VERSION ""

NS_ :

BS_:

BU_: Test ECU

BO_ 513 Diag_Resp: 8 ECU
 SG_ Resp : 0|8@1- (1,0) [0|0] ""  Test

BO_ 512 Diag_Req: 8 Test
 SG_ Req : 0|8@1- (1,0) [0|0] "" Vector__XXX

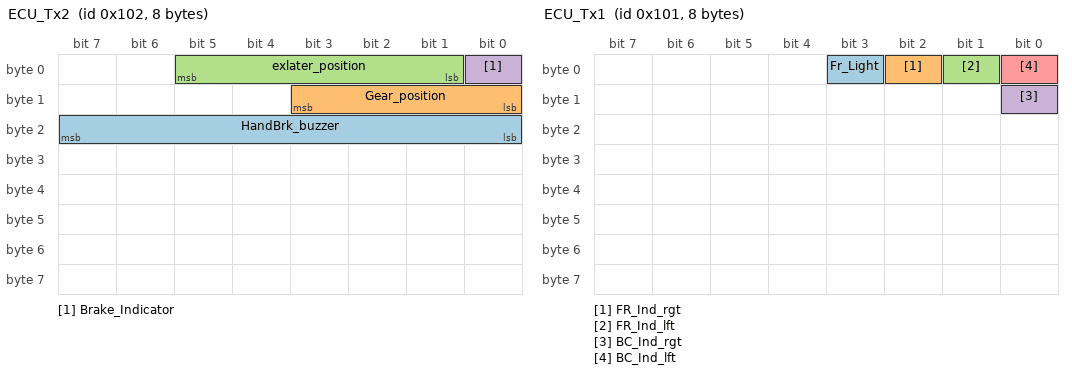
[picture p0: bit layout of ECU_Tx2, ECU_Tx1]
BO_ 258 ECU_Tx2: 8 ECU
 SG_ HandBrk_buzzer : 16|8@1- (1,0) [0|3] "" Vector__XXX
 SG_ Gear_position : 8|4@1+ (1,0) [0|6] ""  ECU
 SG_ exlater_position : 1|5@1+ (1,0) [0|31] ""  ECU
 SG_ Brake_Indicator : 0|1@1- (1,0) [0|1] ""  ECU

BO_ 257 ECU_Tx1: 8 ECU
 SG_ Fr_Light : 3|1@1- (1,0) [0|1] ""  ECU
 SG_ FR_Ind_rgt : 2|1@1- (1,0) [0|1] ""  ECU
 SG_ FR_Ind_lft : 1|1@1- (1,0) [0|1] ""  ECU
 SG_ BC_Ind_rgt : 8|1@1- (1,0) [0|1] ""  ECU
 SG_ BC_Ind_lft : 0|1@1- (1,0) [0|1] ""  ECU

BO_ 1281 ENGmsg: 8 ECU
 SG_ HandBreak_pos : 16|8@1- (1,0) [0|3] "" Vector__XXX
 SG_ Speed : 0|16@1+ (1,0) [0|65535] "" Vector__XXX

EV_ EnvKlemme30: 0 [0|1] "" 1 1 DUMMY_NODE_VECTOR0 Vector__XXX;

EV_ EnvKlemme15: 0 [0|1] "" 0 2 DUMMY_NODE_VECTOR0 Vector__XXX;

BA_DEF_ BU_  "NodeLayerModules" STRING ;
BA_DEF_ BO_  "GenMsgILSupport" ENUM  "No","Yes";
BA_DEF_  "NmBaseAddress" HEX 1024 1087;
BA_DEF_  "BusType" STRING ;
BA_DEF_ BO_  "GenMsgCycleTime" INT 0 50000;
BA_DEF_ BO_  "GenMsgSendType" ENUM  "Cyclic","NotUsed","NotUsed","NotUsed","NotUsed","NotUsed","NotUsed","IfActive","NoMsgSendType","NotUsed","vector_leerstring";
BA_DEF_ SG_  "GenSigSendType" ENUM  "Cyclic","OnWrite","OnWriteWithRepetition","OnChange","OnChangeWithRepetition","IfActive","IfActiveWithRepetition","NoSigSendType","NotUsed","NotUsed","NotUsed","NotUsed","NotUsed";
BA_DEF_DEF_  "NodeLayerModules" "CANoeILNLVector.dll";
BA_DEF_DEF_  "GenMsgILSupport" "Yes";
BA_DEF_DEF_  "NmBaseAddress" 1024;
BA_DEF_DEF_  "BusType" "";
BA_DEF_DEF_  "GenMsgCycleTime" 0;
BA_DEF_DEF_  "GenMsgSendType" "NoMsgSendType";
BA_DEF_DEF_  "GenSigSendType" "Cyclic";
BA_ "BusType" "CAN";
BA_ "GenMsgCycleTime" BO_ 1281 200;
